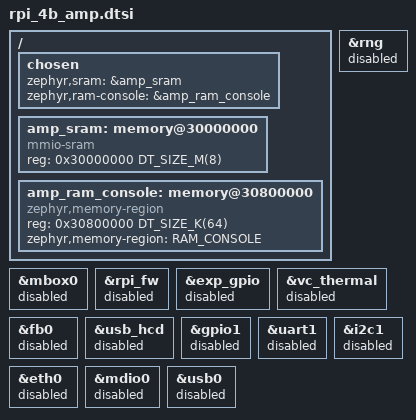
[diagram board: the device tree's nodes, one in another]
/*
 * SPDX-FileCopyrightText: 2026 Muhammad Waleed Badar
 * SPDX-License-Identifier: Apache-2.0
 */

/ {
	chosen {
		/delete-property/ zephyr,console;
		/delete-property/ zephyr,shell-uart;
		/delete-property/ zephyr,entropy;
		/delete-property/ zephyr,display;
		/delete-property/ zephyr,pcie-controller;
		zephyr,sram = &amp_sram;
		zephyr,ram-console = &amp_ram_console;
	};

	amp_sram: memory@30000000 {
		compatible = "mmio-sram";
		reg = <0x30000000 DT_SIZE_M(8)>;
		device_type = "memory";
	};

	amp_ram_console: memory@30800000 {
		compatible = "zephyr,memory-region";
		reg = <0x30800000 DT_SIZE_K(64)>;
		zephyr,memory-region = "RAM_CONSOLE";
	};
};

/delete-node/ &dram0;

&rng {
	status = "disabled";
};

&mbox0 {
	status = "disabled";
};

&rpi_fw {
	status = "disabled";
};

&exp_gpio {
	status = "disabled";
};

&vc_thermal {
	status = "disabled";
};

&fb0 {
	status = "disabled";
};

&usb_hcd {
	status = "disabled";
};

&gpio1 {
	status = "disabled";
};

&uart1 {
	status = "disabled";
};

&i2c1 {
	status = "disabled";
};

&eth0 {
	status = "disabled";
};

&mdio0 {
	status = "disabled";
};

&usb0 {
	status = "disabled";
};
